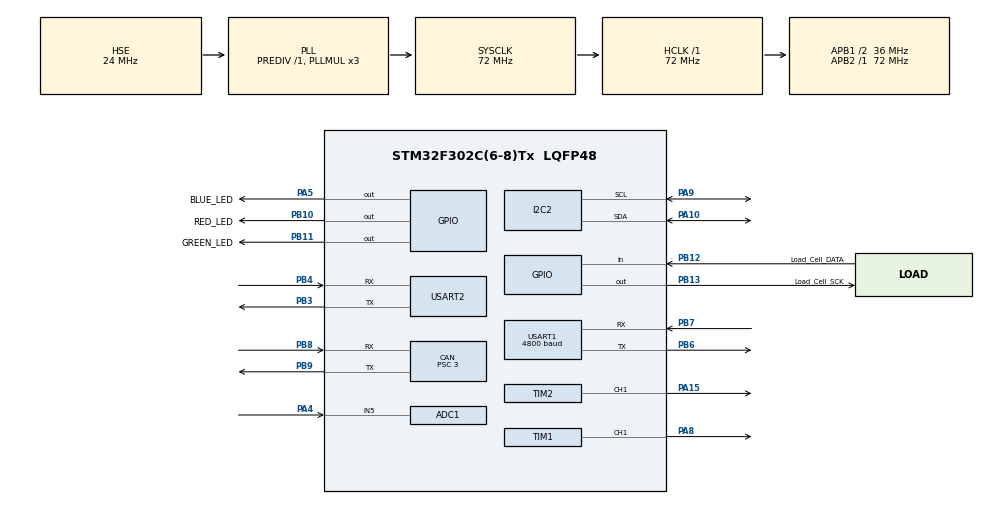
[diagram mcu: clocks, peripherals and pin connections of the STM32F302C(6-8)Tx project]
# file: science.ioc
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ADC1.Channel-0\#ChannelRegularConversion=ADC_CHANNEL_5
ADC1.NbrOfConversionFlag=1
ADC1.Offset-0\#ChannelRegularConversion=0
ADC1.OffsetNumber-0\#ChannelRegularConversion=ADC_OFFSET_NONE
ADC1.Rank-0\#ChannelRegularConversion=1
ADC1.SamplingTime-0\#ChannelRegularConversion=ADC_SAMPLETIME_1CYCLE_5
ADC1.SamplingTimeOPAMP-0\#ChannelRegularConversion=ADC_SAMPLETIME_61CYCLES_5
ADC1.master=1
CAN.ABOM=ENABLE
CAN.BS1=CAN_BS1_7TQ
CAN.BS2=CAN_BS2_4TQ
CAN.CalculateBaudRate=999999
CAN.CalculateTimeBit=1000
CAN.CalculateTimeQuantum=83.33333333333334
CAN.NART=ENABLE
CAN.Prescaler=3
I2C2.Timing=0x00201D2B
Mcu.Family=STM32F3
Mcu.Name=STM32F302C(6-8)Tx
Mcu.Package=LQFP48
NVIC.CAN_RX1_IRQn=true\:0\:0\:false\:false\:true\:true\:true\:true
NVIC.PriorityGroup=NVIC_PRIORITYGROUP_4
PA10.Mode=I2C
PA10.Signal=I2C2_SDA
PA15.Signal=S_TIM2_CH1_ETR
PA4.Mode=IN5-Single-Ended
PA4.Signal=ADC1_IN5
PA5.GPIO_Label=BLUE_LED
PA5.Signal=GPIO_Output
PA8.Signal=S_TIM1_CH1
PA9.Mode=I2C
PA9.Signal=I2C2_SCL
PB10.GPIO_Label=RED_LED
PB10.Signal=GPIO_Output
PB11.GPIO_Label=GREEN_LED
PB11.Signal=GPIO_Output
PB12.GPIO_Label=Load_Cell_DATA
PB12.Signal=GPIO_Input
PB13.GPIO_Label=Load_Cell_SCK
PB13.Signal=GPIO_Output
PB3.Mode=Asynchronous
PB3.Signal=USART2_TX
PB4.Mode=Asynchronous
PB4.Signal=USART2_RX
PB6.Mode=Asynchronous
PB6.Signal=USART1_TX
PB7.Mode=Asynchronous
PB7.Signal=USART1_RX
PB8.Mode=CAN_Activate
PB8.Signal=CAN_RX
PB9.Mode=CAN_Activate
PB9.Signal=CAN_TX
PF0-OSC_IN.Mode=HSE-External-Clock-Source
PF0-OSC_IN.Signal=RCC_OSC_IN
ProjectManager.HeapSize=0x200
ProjectManager.StackSize=0x400
ProjectManager.TargetToolchain=STM32CubeIDE
RCC.AHBFreq_Value=72000000
RCC.APB1CLKDivider=RCC_HCLK_DIV2
RCC.APB1Freq_Value=36000000
RCC.APB1TimFreq_Value=72000000
RCC.APB2Freq_Value=72000000
RCC.APB2TimFreq_Value=72000000
RCC.CortexFreq_Value=72000000
RCC.HCLKFreq_Value=72000000
RCC.HSE_VALUE=24000000
RCC.HSI_VALUE=8000000
RCC.LSE_VALUE=32768
RCC.PLLMUL=RCC_PLL_MUL3
RCC.PLLSourceVirtual=RCC_PLLSOURCE_HSE
RCC.SYSCLKFreq_VALUE=72000000
RCC.SYSCLKSourceVirtual=RCC_SYSCLKSOURCE_PLLCLK
RCC.USBFreq_Value=72000000
SH.S_TIM1_CH1.0=TIM1_CH1,PWM Generation1 CH1
SH.S_TIM2_CH1_ETR.0=TIM2_CH1,PWM Generation1 CH1
TIM1.Channel-PWM\ Generation1\ CH1=TIM_CHANNEL_1
TIM1.Period=1000-1
TIM2.Channel-PWM\ Generation1\ CH1=TIM_CHANNEL_1
USART1.BaudRate=4800
USART1.VirtualMode-Asynchronous=VM_ASYNC
USART2.VirtualMode-Asynchronous=VM_ASYNC
board=custom

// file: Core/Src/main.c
/* USER CODE BEGIN Header */
/**
  ******************************************************************************
  * @file           : main.c
  * @brief          : Main program body
  ******************************************************************************
  * @attention
  *
  * Copyright (c) 2026 STMicroelectronics.
  * All rights reserved.
  *
  * This software is licensed under terms that can be found in the LICENSE file
  * in the root directory of this software component.
  * If no LICENSE file comes with this software, it is provided AS-IS.
  *
  ******************************************************************************
  */
/* USER CODE END Header */
#include "main.h"

/* USER CODE BEGIN Includes */

#include "can_handler.h"

/* USER CODE END Includes */

ADC_HandleTypeDef hadc1;

CAN_HandleTypeDef hcan;

I2C_HandleTypeDef hi2c2;

TIM_HandleTypeDef htim1;
TIM_HandleTypeDef htim2;

UART_HandleTypeDef huart1;
UART_HandleTypeDef huart2;

void SystemClock_Config(void);
static void MX_GPIO_Init(void);
static void MX_CAN_Init(void);
static void MX_ADC1_Init(void);
static void MX_I2C2_Init(void);
static void MX_TIM1_Init(void);
static void MX_TIM2_Init(void);
static void MX_USART1_UART_Init(void);
static void MX_USART2_UART_Init(void);

int main(void)
{

  /* MCU Configuration--------------------------------------------------------*/

  /* Reset of all peripherals, Initializes the Flash interface and the Systick. */
  HAL_Init();

  /* Configure the system clock */
  SystemClock_Config();

  /* Initialize all configured peripherals */
  MX_GPIO_Init();
  MX_CAN_Init();
  MX_ADC1_Init();
  MX_I2C2_Init();
  MX_TIM1_Init();
  MX_TIM2_Init();
  MX_USART1_UART_Init();
  MX_USART2_UART_Init();
  /* USER CODE BEGIN 2 */

  if(HAL_CAN_Start(&hcan) != HAL_OK) Error_Handler();
  HAL_CAN_ActivateNotification(&hcan, CAN_IT_RX_FIFO1_MSG_PENDING);

  /* USER CODE END 2 */

  /* Infinite loop */
  while (1)
  {

  }
}

void SystemClock_Config(void)
{
  RCC_OscInitTypeDef RCC_OscInitStruct = {0};
  RCC_ClkInitTypeDef RCC_ClkInitStruct = {0};
  RCC_PeriphCLKInitTypeDef PeriphClkInit = {0};

  /** Initializes the RCC Oscillators according to the specified parameters
  * in the RCC_OscInitTypeDef structure.
  */
  RCC_OscInitStruct.OscillatorType = RCC_OSCILLATORTYPE_HSI|RCC_OSCILLATORTYPE_HSE;
  RCC_OscInitStruct.HSEState = RCC_HSE_BYPASS;
  RCC_OscInitStruct.HSEPredivValue = RCC_HSE_PREDIV_DIV1;
  RCC_OscInitStruct.HSIState = RCC_HSI_ON;
  RCC_OscInitStruct.HSICalibrationValue = RCC_HSICALIBRATION_DEFAULT;
  RCC_OscInitStruct.PLL.PLLState = RCC_PLL_ON;
  RCC_OscInitStruct.PLL.PLLSource = RCC_PLLSOURCE_HSE;
  RCC_OscInitStruct.PLL.PLLMUL = RCC_PLL_MUL3;
  if (HAL_RCC_OscConfig(&RCC_OscInitStruct) != HAL_OK)
  {
    Error_Handler();
  }

  /** Initializes the CPU, AHB and APB buses clocks
  */
  RCC_ClkInitStruct.ClockType = RCC_CLOCKTYPE_HCLK|RCC_CLOCKTYPE_SYSCLK
                              |RCC_CLOCKTYPE_PCLK1|RCC_CLOCKTYPE_PCLK2;
  RCC_ClkInitStruct.SYSCLKSource = RCC_SYSCLKSOURCE_PLLCLK;
  RCC_ClkInitStruct.AHBCLKDivider = RCC_SYSCLK_DIV1;
  RCC_ClkInitStruct.APB1CLKDivider = RCC_HCLK_DIV2;
  RCC_ClkInitStruct.APB2CLKDivider = RCC_HCLK_DIV1;

  if (HAL_RCC_ClockConfig(&RCC_ClkInitStruct, FLASH_LATENCY_2) != HAL_OK)
  {
    Error_Handler();
  }
  PeriphClkInit.PeriphClockSelection = RCC_PERIPHCLK_USART1|RCC_PERIPHCLK_I2C2
                              |RCC_PERIPHCLK_TIM1|RCC_PERIPHCLK_ADC1;
  PeriphClkInit.Usart1ClockSelection = RCC_USART1CLKSOURCE_PCLK1;
  PeriphClkInit.I2c2ClockSelection = RCC_I2C2CLKSOURCE_HSI;
  PeriphClkInit.Tim1ClockSelection = RCC_TIM1CLK_HCLK;
  PeriphClkInit.Adc1ClockSelection = RCC_ADC1PLLCLK_DIV1;

  if (HAL_RCCEx_PeriphCLKConfig(&PeriphClkInit) != HAL_OK)
  {
    Error_Handler();
  }
}

static void MX_ADC1_Init(void)
{

  ADC_ChannelConfTypeDef sConfig = {0};

  /** Common config
  */
  hadc1.Instance = ADC1;
  hadc1.Init.ClockPrescaler = ADC_CLOCK_ASYNC_DIV1;
  hadc1.Init.Resolution = ADC_RESOLUTION_12B;
  hadc1.Init.ScanConvMode = ADC_SCAN_DISABLE;
  hadc1.Init.ContinuousConvMode = DISABLE;
  hadc1.Init.DiscontinuousConvMode = DISABLE;
  hadc1.Init.ExternalTrigConvEdge = ADC_EXTERNALTRIGCONVEDGE_NONE;
  hadc1.Init.ExternalTrigConv = ADC_SOFTWARE_START;
  hadc1.Init.DataAlign = ADC_DATAALIGN_RIGHT;
  hadc1.Init.NbrOfConversion = 1;
  hadc1.Init.DMAContinuousRequests = DISABLE;
  hadc1.Init.EOCSelection = ADC_EOC_SINGLE_CONV;
  hadc1.Init.LowPowerAutoWait = DISABLE;
  hadc1.Init.Overrun = ADC_OVR_DATA_OVERWRITTEN;
  if (HAL_ADC_Init(&hadc1) != HAL_OK)
  {
    Error_Handler();
  }

  /** Configure Regular Channel
  */
  sConfig.Channel = ADC_CHANNEL_5;
  sConfig.Rank = ADC_REGULAR_RANK_1;
  sConfig.SingleDiff = ADC_SINGLE_ENDED;
  sConfig.SamplingTime = ADC_SAMPLETIME_1CYCLE_5;
  sConfig.OffsetNumber = ADC_OFFSET_NONE;
  sConfig.Offset = 0;
  if (HAL_ADC_ConfigChannel(&hadc1, &sConfig) != HAL_OK)
  {
    Error_Handler();
  }

}

static void MX_CAN_Init(void)
{

  hcan.Instance = CAN;
  hcan.Init.Prescaler = 3;
  hcan.Init.Mode = CAN_MODE_NORMAL;
  hcan.Init.SyncJumpWidth = CAN_SJW_1TQ;
  hcan.Init.TimeSeg1 = CAN_BS1_7TQ;
  hcan.Init.TimeSeg2 = CAN_BS2_4TQ;
  hcan.Init.TimeTriggeredMode = DISABLE;
  hcan.Init.AutoBusOff = ENABLE;
  hcan.Init.AutoWakeUp = DISABLE;
  hcan.Init.AutoRetransmission = ENABLE;
  hcan.Init.ReceiveFifoLocked = DISABLE;
  hcan.Init.TransmitFifoPriority = DISABLE;
  if (HAL_CAN_Init(&hcan) != HAL_OK)
  {
    Error_Handler();
  }
  /* USER CODE BEGIN CAN_Init 2 */

  CAN_CONFIG(&hcan);

  /* USER CODE END CAN_Init 2 */

}

static void MX_I2C2_Init(void)
{

  hi2c2.Instance = I2C2;
  hi2c2.Init.Timing = 0x00201D2B;
  hi2c2.Init.OwnAddress1 = 0;
  hi2c2.Init.AddressingMode = I2C_ADDRESSINGMODE_7BIT;
  hi2c2.Init.DualAddressMode = I2C_DUALADDRESS_DISABLE;
  hi2c2.Init.OwnAddress2 = 0;
  hi2c2.Init.OwnAddress2Masks = I2C_OA2_NOMASK;
  hi2c2.Init.GeneralCallMode = I2C_GENERALCALL_DISABLE;
  hi2c2.Init.NoStretchMode = I2C_NOSTRETCH_DISABLE;
  if (HAL_I2C_Init(&hi2c2) != HAL_OK)
  {
    Error_Handler();
  }

  /** Configure Analogue filter
  */
  if (HAL_I2CEx_ConfigAnalogFilter(&hi2c2, I2C_ANALOGFILTER_ENABLE) != HAL_OK)
  {
    Error_Handler();
  }

  /** Configure Digital filter
  */
  if (HAL_I2CEx_ConfigDigitalFilter(&hi2c2, 0) != HAL_OK)
  {
    Error_Handler();
  }

}

static void MX_TIM1_Init(void)
{

  TIM_MasterConfigTypeDef sMasterConfig = {0};
  TIM_OC_InitTypeDef sConfigOC = {0};
  TIM_BreakDeadTimeConfigTypeDef sBreakDeadTimeConfig = {0};

  htim1.Instance = TIM1;
  htim1.Init.Prescaler = 0;
  htim1.Init.CounterMode = TIM_COUNTERMODE_UP;
  htim1.Init.Period = 1000-1;
  htim1.Init.ClockDivision = TIM_CLOCKDIVISION_DIV1;
  htim1.Init.RepetitionCounter = 0;
  htim1.Init.AutoReloadPreload = TIM_AUTORELOAD_PRELOAD_DISABLE;
  if (HAL_TIM_PWM_Init(&htim1) != HAL_OK)
  {
    Error_Handler();
  }
  sMasterConfig.MasterOutputTrigger = TIM_TRGO_RESET;
  sMasterConfig.MasterOutputTrigger2 = TIM_TRGO2_RESET;
  sMasterConfig.MasterSlaveMode = TIM_MASTERSLAVEMODE_DISABLE;
  if (HAL_TIMEx_MasterConfigSynchronization(&htim1, &sMasterConfig) != HAL_OK)
  {
    Error_Handler();
  }
  sConfigOC.OCMode = TIM_OCMODE_PWM1;
  sConfigOC.Pulse = 0;
  sConfigOC.OCPolarity = TIM_OCPOLARITY_HIGH;
  sConfigOC.OCNPolarity = TIM_OCNPOLARITY_HIGH;
  sConfigOC.OCFastMode = TIM_OCFAST_DISABLE;
  sConfigOC.OCIdleState = TIM_OCIDLESTATE_RESET;
  sConfigOC.OCNIdleState = TIM_OCNIDLESTATE_RESET;
  if (HAL_TIM_PWM_ConfigChannel(&htim1, &sConfigOC, TIM_CHANNEL_1) != HAL_OK)
  {
    Error_Handler();
  }
  sBreakDeadTimeConfig.OffStateRunMode = TIM_OSSR_DISABLE;
  sBreakDeadTimeConfig.OffStateIDLEMode = TIM_OSSI_DISABLE;
  sBreakDeadTimeConfig.LockLevel = TIM_LOCKLEVEL_OFF;
  sBreakDeadTimeConfig.DeadTime = 0;
  sBreakDeadTimeConfig.BreakState = TIM_BREAK_DISABLE;
  sBreakDeadTimeConfig.BreakPolarity = TIM_BREAKPOLARITY_HIGH;
  sBreakDeadTimeConfig.BreakFilter = 0;
  sBreakDeadTimeConfig.Break2State = TIM_BREAK2_DISABLE;
  sBreakDeadTimeConfig.Break2Polarity = TIM_BREAK2POLARITY_HIGH;
  sBreakDeadTimeConfig.Break2Filter = 0;
  sBreakDeadTimeConfig.AutomaticOutput = TIM_AUTOMATICOUTPUT_DISABLE;
  if (HAL_TIMEx_ConfigBreakDeadTime(&htim1, &sBreakDeadTimeConfig) != HAL_OK)
  {
    Error_Handler();
  }
  HAL_TIM_MspPostInit(&htim1);

}

static void MX_TIM2_Init(void)
{

  TIM_MasterConfigTypeDef sMasterConfig = {0};
  TIM_OC_InitTypeDef sConfigOC = {0};

  htim2.Instance = TIM2;
  htim2.Init.Prescaler = 0;
  htim2.Init.CounterMode = TIM_COUNTERMODE_UP;
  htim2.Init.Period = 4294967295;
  htim2.Init.ClockDivision = TIM_CLOCKDIVISION_DIV1;
  htim2.Init.AutoReloadPreload = TIM_AUTORELOAD_PRELOAD_DISABLE;
  if (HAL_TIM_PWM_Init(&htim2) != HAL_OK)
  {
    Error_Handler();
  }
  sMasterConfig.MasterOutputTrigger = TIM_TRGO_RESET;
  sMasterConfig.MasterSlaveMode = TIM_MASTERSLAVEMODE_DISABLE;
  if (HAL_TIMEx_MasterConfigSynchronization(&htim2, &sMasterConfig) != HAL_OK)
  {
    Error_Handler();
  }
  sConfigOC.OCMode = TIM_OCMODE_PWM1;
  sConfigOC.Pulse = 0;
  sConfigOC.OCPolarity = TIM_OCPOLARITY_HIGH;
  sConfigOC.OCFastMode = TIM_OCFAST_DISABLE;
  if (HAL_TIM_PWM_ConfigChannel(&htim2, &sConfigOC, TIM_CHANNEL_1) != HAL_OK)
  {
    Error_Handler();
  }
  HAL_TIM_MspPostInit(&htim2);

}

static void MX_USART1_UART_Init(void)
{

  huart1.Instance = USART1;
  huart1.Init.BaudRate = 4800;
  huart1.Init.WordLength = UART_WORDLENGTH_8B;
  huart1.Init.StopBits = UART_STOPBITS_1;
  huart1.Init.Parity = UART_PARITY_NONE;
  huart1.Init.Mode = UART_MODE_TX_RX;
  huart1.Init.HwFlowCtl = UART_HWCONTROL_NONE;
  huart1.Init.OverSampling = UART_OVERSAMPLING_16;
  huart1.Init.OneBitSampling = UART_ONE_BIT_SAMPLE_DISABLE;
  huart1.AdvancedInit.AdvFeatureInit = UART_ADVFEATURE_NO_INIT;
  if (HAL_UART_Init(&huart1) != HAL_OK)
  {
    Error_Handler();
  }

}

static void MX_USART2_UART_Init(void)
{

  huart2.Instance = USART2;
  huart2.Init.BaudRate = 38400;
  huart2.Init.WordLength = UART_WORDLENGTH_8B;
  huart2.Init.StopBits = UART_STOPBITS_1;
  huart2.Init.Parity = UART_PARITY_NONE;
  huart2.Init.Mode = UART_MODE_TX_RX;
  huart2.Init.HwFlowCtl = UART_HWCONTROL_NONE;
  huart2.Init.OverSampling = UART_OVERSAMPLING_16;
  huart2.Init.OneBitSampling = UART_ONE_BIT_SAMPLE_DISABLE;
  huart2.AdvancedInit.AdvFeatureInit = UART_ADVFEATURE_NO_INIT;
  if (HAL_UART_Init(&huart2) != HAL_OK)
  {
    Error_Handler();
  }

}

static void MX_GPIO_Init(void)
{
  GPIO_InitTypeDef GPIO_InitStruct = {0};

  /* GPIO Ports Clock Enable */
  __HAL_RCC_GPIOF_CLK_ENABLE();
  __HAL_RCC_GPIOA_CLK_ENABLE();
  __HAL_RCC_GPIOB_CLK_ENABLE();

  /*Configure GPIO pin Output Level */
  HAL_GPIO_WritePin(BLUE_LED_GPIO_Port, BLUE_LED_Pin, GPIO_PIN_RESET);

  /*Configure GPIO pin Output Level */
  HAL_GPIO_WritePin(GPIOB, RED_LED_Pin|GREEN_LED_Pin|Load_Cell_SCK_Pin, GPIO_PIN_RESET);

  /*Configure GPIO pin : BLUE_LED_Pin */
  GPIO_InitStruct.Pin = BLUE_LED_Pin;
  GPIO_InitStruct.Mode = GPIO_MODE_OUTPUT_PP;
  GPIO_InitStruct.Pull = GPIO_NOPULL;
  GPIO_InitStruct.Speed = GPIO_SPEED_FREQ_LOW;
  HAL_GPIO_Init(BLUE_LED_GPIO_Port, &GPIO_InitStruct);

  /*Configure GPIO pins : RED_LED_Pin GREEN_LED_Pin Load_Cell_SCK_Pin */
  GPIO_InitStruct.Pin = RED_LED_Pin|GREEN_LED_Pin|Load_Cell_SCK_Pin;
  GPIO_InitStruct.Mode = GPIO_MODE_OUTPUT_PP;
  GPIO_InitStruct.Pull = GPIO_NOPULL;
  GPIO_InitStruct.Speed = GPIO_SPEED_FREQ_LOW;
  HAL_GPIO_Init(GPIOB, &GPIO_InitStruct);

  /*Configure GPIO pin : Load_Cell_DATA_Pin */
  GPIO_InitStruct.Pin = Load_Cell_DATA_Pin;
  GPIO_InitStruct.Mode = GPIO_MODE_INPUT;
  GPIO_InitStruct.Pull = GPIO_NOPULL;
  HAL_GPIO_Init(Load_Cell_DATA_GPIO_Port, &GPIO_InitStruct);

}

void Error_Handler(void)
{
  __disable_irq();
  while (1)
  {
  }
}
